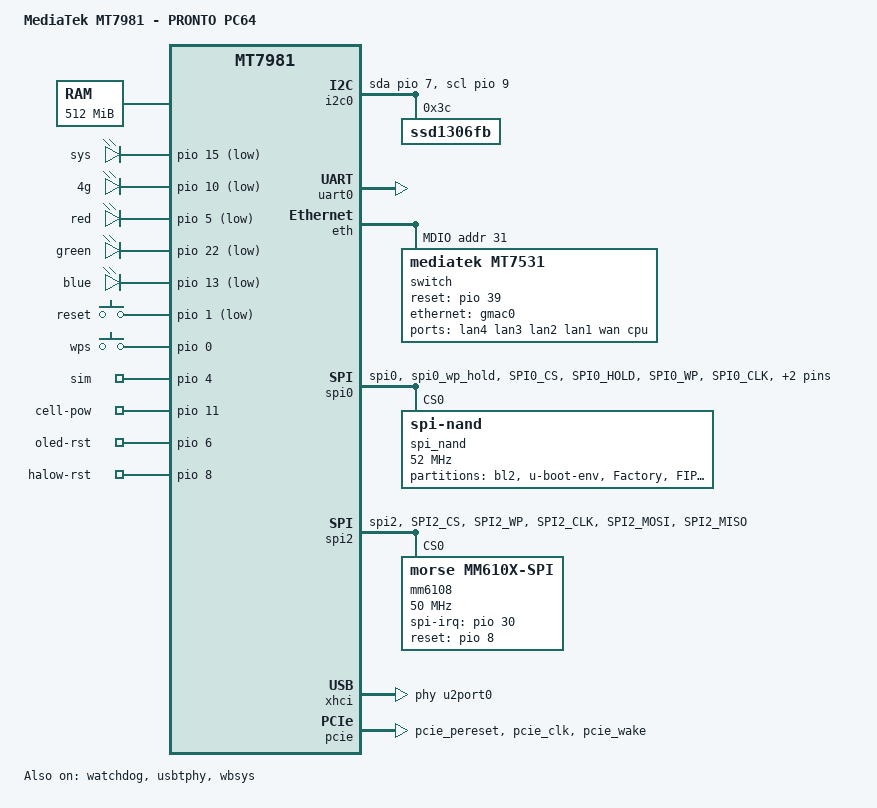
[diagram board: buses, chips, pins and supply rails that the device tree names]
/dts-v1/;
#include "mt7981.dtsi"
/ {
        model = "MediaTek MT7981 - PRONTO PC64";
        compatible = "pronto,pc64";
        chosen {
                bootargs = "console=ttyS0,115200n1 loglevel=8  \
                                earlycon=uart8250,mmio32,0x11002000";
        };

        memory {
                // fpga ddr2: 128MB*2
                reg = <0 0x40000000 0 0x20000000>;
        };

	leds {
		compatible = "gpio-leds";

		sys {
			label = "sys";
			gpios = <&pio 15 GPIO_ACTIVE_LOW>;
		};

		4g {
			label = "4g";
			gpios = <&pio 10 GPIO_ACTIVE_LOW>;
		};

		red {
			label = "red";
			gpios = <&pio 5 GPIO_ACTIVE_LOW>;
		};

		green {
			label = "green";
			gpios = <&pio 22 GPIO_ACTIVE_LOW>;
		};

		blue {
			label = "blue";
			gpios = <&pio 13 GPIO_ACTIVE_LOW>;
		};
	};

        gpio-keys {
                compatible = "gpio-keys";

                reset {
                        label = "reset";
                        linux,code = <KEY_RESTART>;
                        gpios = <&pio 1 GPIO_ACTIVE_LOW>;
                };

                wps {
                        label = "wps";
                        linux,code = <KEY_WPS_BUTTON>;
                        gpios = <&pio 0 GPIO_ACTIVE_HIGH>;
                };
        };

        gpio-export {
                compatible = "gpio-export";
                #size-cells = <0>;

                sim {
                        gpio-export,name = "sim";
                        gpio-export,output = <0>;
                        gpios = <&pio 4 GPIO_ACTIVE_HIGH>;
                };

                cellpow {
                        gpio-export,name = "cell-pow";
                        gpio-export,output = <1>;
                        gpios = <&pio 11 GPIO_ACTIVE_HIGH>;
                };

                oledrst {
                        gpio-export,name = "oled-rst";
                        gpio-export,output = <1>;
                        gpios = <&pio 6 GPIO_ACTIVE_HIGH>;
                };

                halowrst {
                        gpio-export,name = "halow-rst";
                        gpio-export,output = <1>;
                        gpios = <&pio 8 GPIO_ACTIVE_HIGH>;
                };

        };
};

&afe {
        pinctrl-names = "default";
        pinctrl-0 = <&pcm_pins>;
        status = "disabled";
};

/* PC64-V3 i2c from gpio */
&i2c0 {
        compatible = "i2c-gpio";
        gpios = <&pio 7 0>, /* sda*/
        <&pio 9 0>; /* scl*/
        i2c-gpio,sda-is-open-drain;
        i2c-gpio,scl-is-open-drain;
        i2c-gpio,delay-us = <5>;        /* ~100 kHz */
        #address-cells = <1>;
        #size-cells = <0>;
        status = "okay";
        ssd1306fb: ssd1306@3c{
                compatible = "ssd1306fb";
                reg = <0x3c>;
                status = "okay";
        };
};

&uart0 {
        status = "okay";
};

&watchdog {
        status = "okay";
};

&eth {
        status = "okay";

        gmac0: mac@0 {
                compatible = "mediatek,eth-mac";
                reg = <0>;
                phy-mode = "2500base-x";
                nvmem-cell-names = "mac-address";
                nvmem-cells = <&macaddr_factory 0>;

                fixed-link {
                        speed = <2500>;
                        full-duplex;
                        pause;
                };
        };

        mdio: mdio-bus {
                #address-cells = <1>;
                #size-cells = <0>;

                switch@0 {
                        compatible = "mediatek,mt7531";
                        reg = <31>;
                        reset-gpios = <&pio 39 0>;

                        ports {
                                #address-cells = <1>;
                                #size-cells = <0>;

                                port@0 {
                                        reg = <0>;
                                        label = "lan4";
                                };

                                port@1 {
                                        reg = <1>;
                                        label = "lan3";
                                };

                                port@2 {
                                        reg = <2>;
                                        label = "lan2";
                                };

                                port@3 {
                                        reg = <3>;
                                        label = "lan1";
                                };

                                port@4 {
					reg = <4>;
					label = "wan";
					nvmem-cell-names = "mac-address";
					nvmem-cells = <&macaddr_factory 1>;
                                };

                                port@6 {
                                        reg = <6>;
                                        label = "cpu";
                                        ethernet = <&gmac0>;
                                        phy-mode = "2500base-x";

                                        fixed-link {
                                                speed = <2500>;
                                                full-duplex;
                                                pause;
                                        };
                                };
                        };
                };
        };
};

&spi0 {
        pinctrl-names = "default";
        pinctrl-0 = <&spi0_flash_pins>;
        status = "okay";

        spi_nand@0 {
                compatible = "spi-nand";
                #address-cells = <1>;
                #size-cells = <1>;
                reg = <0>;
                forced-create;

                spi-max-frequency = <52000000>;
                spi-tx-bus-width = <4>;
                spi-rx-bus-width = <4>;

                mediatek,nmbm;
                mediatek,bmt-max-ratio = <1>;
                mediatek,bmt-max-reserved-blocks = <64>;

                partitions {
                        compatible = "fixed-partitions";
                        #address-cells = <1>;
                        #size-cells = <1>;

                        partition@0 {
                                label = "bl2";
                                reg = <0x0000000 0x0100000>; //1MB
                                read-only;
                        };

                        partition@100000 {
                                label = "u-boot-env";
                                reg = <0x0100000 0x0080000>; //512KB
                        };

                        factory: partition@180000 {
                                label = "Factory";
                                reg = <0x0180000 0x0200000>; //2MB
                                read-only;

                                nvmem-layout {
					compatible = "fixed-layout";
					#address-cells = <1>;
					#size-cells = <1>;

					eeprom_factory: eeprom@0 {
						reg = <0x0 0x1000>;
					};
					macaddr_factory: macaddr@4 {
						compatible = "mac-base";
						reg = <0x04 0x6>;
						#nvmem-cell-cells = <1>;
					};
                                 };

                         };

                         partition@380000 {
                                 label = "FIP";
                                 reg = <0x0380000 0x0200000>; //2MB
                                 read-only;
                         };

			 partition@580000 {
				 label = "ubi";
				 reg = <0x0580000 0x7800000>; //112MB
			 };
                };
        };
};


&spi1 {
        pinctrl-names = "default";
        pinctrl-0 = <&spic_pins>;
        status = "disabled";

        proslic_spi: proslic_spi@0 {
                compatible = "silabs,proslic_spi";
                reg = <0>;
                spi-max-frequency = <10000000>;
                spi-cpha = <1>;
                spi-cpol = <1>;
                channel_count = <1>;
                debug_level = <4>;       /* 1 = TRC, 2 = DBG, 4 = ERR */
                reset_gpio = <&pio 15 0>;
                ig,enable-spi = <1>;     /* 1: Enable, 0: Disable */
        };
};

&spi2 {
	pinctrl-names = "default";
	pinctrl-0 = <&spi2_flash_pins>;
	status = "okay";

	mm6108: mm6108@0  {
		compatible = "morse,mm610x-spi";
		reg = <0>;
		spi-max-frequency = <50000000>;
		spi-irq-gpios = <&pio 30 0>;
		reset-gpios = <&pio 8 0>;
	};
};

&pio {
	pcie_pins: pcie-pins {
		mux {
			function = "pcie";
			groups = "pcie_pereset", "pcie_clk", "pcie_wake";
		};
	};

        i2c_pins: i2c-pins-g0 {
                mux {
                        function = "i2c";
                        groups = "i2c0_1";
                };
        };

        pcm_pins: pcm-pins-g0 {
                mux {
                        function = "pcm";
                        groups = "pcm";
                };
        };

        pwm0_pin: pwm0-pin-g0 {
                mux {
                        function = "pwm";
                        groups = "pwm0_0";
                };
        };

        pwm1_pin: pwm1-pin-g0 {
                mux {
                        function = "pwm";
                        groups = "pwm1_0";
                };
        };

        pwm2_pin: pwm2-pin {
                mux {
                        function = "pwm";
                        groups = "pwm2";
                };
        };

        spi0_flash_pins: spi0-pins {
                mux {
                        function = "spi";
                        groups = "spi0", "spi0_wp_hold";
                };

                conf-pu {
                        pins = "SPI0_CS", "SPI0_HOLD", "SPI0_WP";
                        drive-strength = <MTK_DRIVE_8mA>;
                        bias-pull-up = <MTK_PUPD_SET_R1R0_11>;
                };

                conf-pd {
                        pins = "SPI0_CLK", "SPI0_MOSI", "SPI0_MISO";
                        drive-strength = <MTK_DRIVE_8mA>;
                        bias-pull-down = <MTK_PUPD_SET_R1R0_11>;
                };
        };

        spi2_flash_pins: spi2-pins {
                mux {
                        function = "spi";
                        groups = "spi2";
                };

                conf-pu {
                        pins = "SPI2_CS", "SPI2_WP";
                        drive-strength = <MTK_DRIVE_8mA>;
                        bias-pull-up = <MTK_PUPD_SET_R1R0_11>;
                };

                conf-pd {
                        pins = "SPI2_CLK", "SPI2_MOSI", "SPI2_MISO";
                        drive-strength = <MTK_DRIVE_8mA>;
                        bias-pull-down = <MTK_PUPD_SET_R1R0_11>;
                };
        };

        spic_pins: spi1-pins {
                mux {
                        function = "spi";
                        groups = "spi1_1";
                };
        };

        uart1_pins: uart1-pins-g1 {
                mux {
                        function = "uart";
                        groups = "uart1_1";
                };
        };

        uart2_pins: uart2-pins-g1 {
                mux {
                        function = "uart";
                        groups = "uart2_1";
                };
        };
};

&usbtphy {
        status = "okay";
};

&xhci {
        mediatek,u3p-dis-msk = <0x0>;
        phys = <&u2port0 PHY_TYPE_USB2>,
               <&u3port0 PHY_TYPE_USB3>;
        status = "okay";
};

&wbsys {
        status = "okay";
	nvmem-cells = <&eeprom_factory>;
	nvmem-cell-names = "eeprom";
};

&pcie {
	status = "okay";
	pinctrl-names = "default";
	pinctrl-0 = <&pcie_pins>;
	#address-cells = <3>;
	#size-cells = <2>;
};
